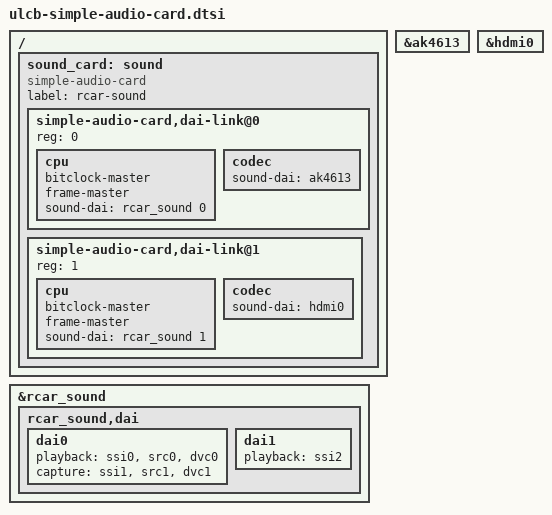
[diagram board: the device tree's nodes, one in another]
/ {
	sound_card: sound {
		compatible = "simple-audio-card";
		label = "rcar-sound";
		#address-cells = <1>;
		#size-cells = <0>;
		simple-audio-card,dai-link@0 {
			reg = <0>;
			cpu {
				bitclock-master;
				frame-master;
				sound-dai = <&rcar_sound 0>;
			};
			codec {
				sound-dai = <&ak4613>;
			};
		};
		simple-audio-card,dai-link@1 {
			reg = <1>;
			cpu {
				bitclock-master;
				frame-master;
				sound-dai = <&rcar_sound 1>;
			};
			codec {
				sound-dai = <&hdmi0>;
			};
		};
	};
};
&ak4613 {
	#sound-dai-cells = <0>;
};
&hdmi0 {
	#sound-dai-cells = <0>;
};
&rcar_sound {
	#sound-dai-cells = <1>;
	rcar_sound,dai {
		dai0 {
			playback = <&ssi0 &src0 &dvc0>;
			capture  = <&ssi1 &src1 &dvc1>;
		};
		dai1 {
			playback = <&ssi2>;
		};
	};
};
